# AT32F415xx register map
Vendor: Keil; Series: AT32F415; File version: 1.0
CPU: CM4 r0p1, little endian, no MPU, FPU, 4 interrupt priority bits
Registers are 32-bit, read-write, reset 0x0 unless marked. A register's access mark holds for its fields unless they carry their own. Offsets are from the block's base; [hi:lo] are bit positions; {n}, {i} and the like mark numbered series; 'fields as' and 'values as' point back to an identical list.

## NVIC — Nested Vectored Interrupt Controller
Base 0xE000E000
0x04 ICTR ro — Interrupt Controller Type Register
  [3:0] INTLINESNUM — Total number of interrupt lines in groups
0x100 ISER0 — Interrupt Set-Enable Register
  [31:0] SETENA
0x104 ISER1 — Interrupt Set-Enable Register
  [31:0] SETENA
0x180 ICER0 — Interrupt Clear-Enable Register
  [31:0] CLRENA
0x184 ICER1 — Interrupt Clear-Enable Register
  [31:0] CLRENA
0x200 ISPR0 — Interrupt Set-Pending Register
  [31:0] SETPEND
0x204 ISPR1 — Interrupt Set-Pending Register
  [31:0] SETPEND
0x280 ICPR0 — Interrupt Clear-Pending Register
  [31:0] CLRPEND
0x284 ICPR1 — Interrupt Clear-Pending Register
  [31:0] CLRPEND
0x300 IABR0 ro — Interrupt Active Bit Register
  [31:0] ACTIVE
0x304 IABR1 ro — Interrupt Active Bit Register
  [31:0] ACTIVE
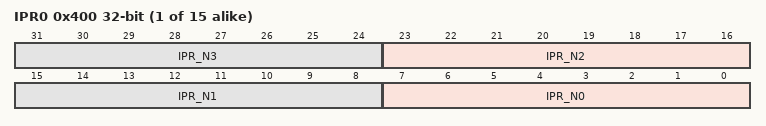
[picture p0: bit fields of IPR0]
{0x400+4i} IPR{i} (i=0..14) — Interrupt Priority Register
  [8n+7:8n] IPR_N{n} (n=0..3)
0xF00 STIR wo — Software Triggered Interrupt Register
  [8:0] INTID — interrupt to be triggered

## USB_OTG_HOST — USB on the go full speed
Base 0x50000400
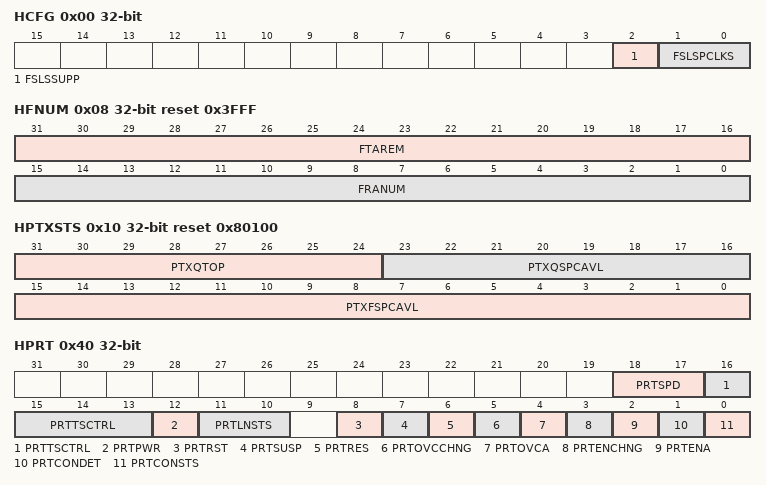
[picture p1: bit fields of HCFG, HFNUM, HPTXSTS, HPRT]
0x00 HCFG — OTG_FS host configuration register (OTG_FS_HCFG)
  [2] FSLSSUPP ro — FS- and LS-only support
  [1:0] FSLSPCLKS — FS/LS PHY clock select
0x04 HFIR reset 0xEA60 — OTG_FS Host frame interval register
  [15:0] FRAINT — Frame interval
0x08 HFNUM ro reset 0x3FFF — OTG_FS host frame number/frame time remaining register (OTG_FS_HFNUM)
  [31:16] FTAREM — Frame time remaining
  [15:0] FRANUM — Frame number
0x10 HPTXSTS reset 0x80100 — OTG_FS_Host periodic transmit FIFO/queue status register (OTG_FS_HPTXSTS)
  [31:24] PTXQTOP ro — Top of the periodic transmit request queue
  [23:16] PTXQSPCAVL ro — Periodic transmit request queue space available
  [15:0] PTXFSPCAVL — Periodic transmit data FIFO space available
0x14 HAINT ro — OTG_FS Host all channels interrupt register
  [15:0] HAINT — Channel interrupts
0x18 HAINTMSK — OTG_FS host all channels interrupt mask register
  [15:0] HAINTM — Channel interrupt mask
0x40 HPRT — OTG_FS host port control and status register (OTG_FS_HPRT)
  [18:17] PRTSPD ro — Port speed
  [16:13] PRTTSCTRL — Port test control
  [12] PRTPWR — Port power
  [11:10] PRTLNSTS ro — Port line status
  [8] PRTRST — Port reset
  [7] PRTSUSP — Port suspend
  [6] PRTRES — Port resume
  [5] PRTOVCCHNG — Port overcurrent change
  [4] PRTOVCA ro — Port overcurrent active
  [3] PRTENCHNG — Port enable/disable change
  [2] PRTENA — Port enable
  [1] PRTCONDET — Port connect detected
  [0] PRTCONSTS ro — Port connect status
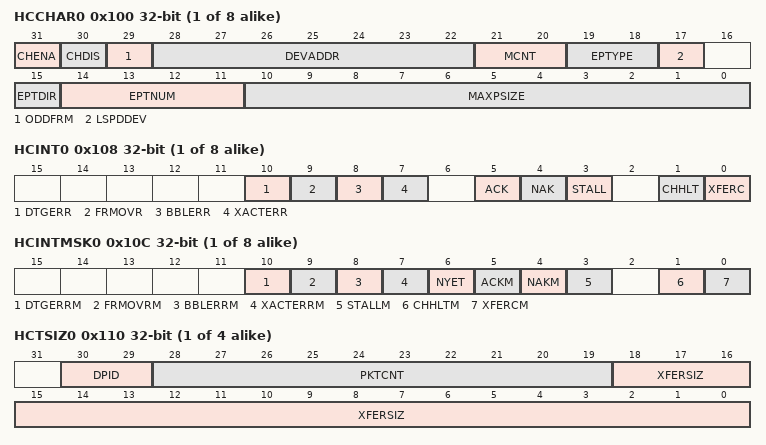
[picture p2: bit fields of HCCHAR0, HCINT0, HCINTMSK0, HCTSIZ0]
{0x100+0x20*i} HCCHAR{i} (i=0..7) — OTG_FS host channel-{i} characteristics register (OTG_FS_HCCHAR{i})
  [31] CHENA — Channel enable
  [30] CHDIS — Channel disable
  [29] ODDFRM — Odd frame
  [28:22] DEVADDR — Device address
  [21:20] MCNT — Multicount
  [19:18] EPTYPE — Endpoint type
  [17] LSPDDEV — Low-speed device
  [15] EPTDIR — Endpoint direction
  [14:11] EPTNUM — Endpoint number
  [10:0] MAXPSIZE — Maximum packet size
{0x108+0x20*i} HCINT{i} (i=0..7) — OTG_FS host channel-{i} interrupt register (OTG_FS_HCINT{i})
  [10] DTGERR — Data toggle error
  [9] FRMOVR — Frame overrun
  [8] BBLERR — Babble error
  [7] XACTERR — Transaction error
  [5] ACK — ACK response received/transmitted interrupt
  [4] NAK — NAK response received interrupt
  [3] STALL — STALL response received interrupt
  [1] CHHLT — Channel halted
  [0] XFERC — Transfer completed
{0x10C+0x20*i} HCINTMSK{i} (i=0..7) — OTG_FS host channel-{i} mask register (OTG_FS_HCINTMSK{i})
  [10] DTGERRM — Data toggle error mask
  [9] FRMOVRM — Frame overrun mask
  [8] BBLERRM — Babble error mask
  [7] XACTERRM — Transaction error mask
  [6] NYET — response received interrupt mask
  [5] ACKM — ACK response received/transmitted interrupt mask
  [4] NAKM — NAK response received interrupt mask
  [3] STALLM — STALL response received interrupt mask
  [1] CHHLTM — Channel halted mask
  [0] XFERCM — Transfer completed mask
{0x110+0x20*i} HCTSIZ{i} (i=0..3) — OTG_FS host channel-{i} transfer size register
  [30:29] DPID — Data PID
  [28:19] PKTCNT — Packet count
  [18:0] XFERSIZ — Transfer size
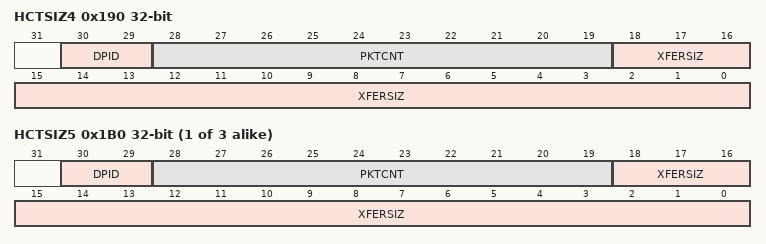
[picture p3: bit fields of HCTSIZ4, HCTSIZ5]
0x190 HCTSIZ4 — OTG_FS host channel-x transfer size register
  fields as HCTSIZ0
{0x110+0x20*i} HCTSIZ{i} (i=5..7) — OTG_FS host channel-{i} transfer size register
  fields as HCTSIZ0

## USB_OTG_PWRCLK — USB on the go full speed
Base 0x50000E00
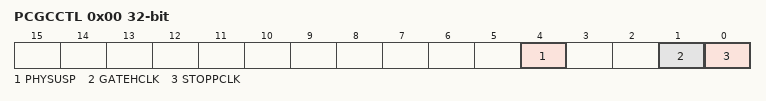
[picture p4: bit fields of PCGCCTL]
0x00 PCGCCTL ro — OTG_FS power and clock gating control register (OTG_FS_PCGCCTL)
  [4] PHYSUSP — PHY Suspended
  [1] GATEHCLK
  [0] STOPPCLK — Stop PHY clock
